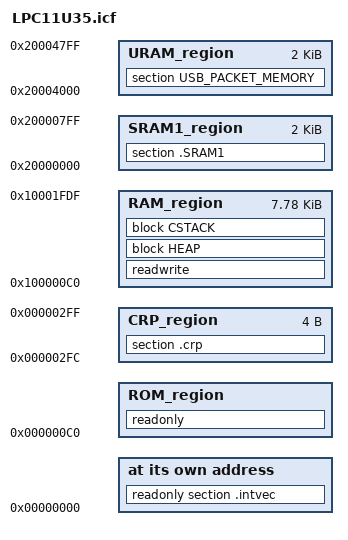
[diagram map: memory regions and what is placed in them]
/*###ICF### Section handled by ICF editor, don't touch! ****/
/*-Editor annotation file-*/
/* IcfEditorFile="$TOOLKIT_DIR$\config\ide\IcfEditor\cortex_v1_0.xml" */
/*-Specials-*/
define symbol __ICFEDIT_intvec_start__ = 0x00000000;
/*-Memory Regions-*/
define symbol __ICFEDIT_region_ROM_start__   = 0x000000C0;
define symbol __ICFEDIT_region_ROM_end__     = 0x0000FFFF;
define symbol __ICFEDIT_region_NVIC_start__   = 0x10000000;
define symbol __ICFEDIT_region_NVIC_end__   = 0x100000BF;
define symbol __ICFEDIT_region_RAM_start__   = 0x100000C0;
define symbol __ICFEDIT_region_RAM_end__     = 0x10001FDF;
/*-Sizes-*/
define symbol __ICFEDIT_size_cstack__   = 0x400;
define symbol __ICFEDIT_size_heap__     = 0x800;
/**** End of ICF editor section. ###ICF###*/

define symbol __CRP_start__   = 0x000002FC;
define symbol __CRP_end__     = 0x000002FF;

define symbol __URAM_start__  = 0x20004000;
define symbol __URAM_end__    = 0x200047FF;

define symbol __SRAM1_start__ = 0x20000000;
define symbol __SRAM1_end__   = 0x200007FF;

define memory mem with size = 4G;
define region ROM_region   = mem:[from __ICFEDIT_region_ROM_start__   to __ICFEDIT_region_ROM_end__] -  mem:[from  __CRP_start__ to __CRP_end__];
define region RAM_region   = mem:[from __ICFEDIT_region_RAM_start__   to __ICFEDIT_region_RAM_end__];
define region URAM_region  = mem:[from __URAM_start__  to __URAM_end__];
define region SRAM1_region = mem:[from __SRAM1_start__ to __SRAM1_end__];
define region CRP_region   = mem:[from __CRP_start__ to __CRP_end__];

define block CSTACK    with alignment = 8, size = __ICFEDIT_size_cstack__   { };
define block HEAP      with alignment = 8, size = __ICFEDIT_size_heap__     { };

initialize by copy { readwrite };
do not initialize  { section .noinit };

place at address mem:__ICFEDIT_intvec_start__ { readonly section .intvec };
place in ROM_region   { readonly };
place in RAM_region   { readwrite,
                        block HEAP, block CSTACK };
place in CRP_region   { section .crp };
place in URAM_region  { section USB_PACKET_MEMORY };
place in SRAM1_region { section .SRAM1 };
